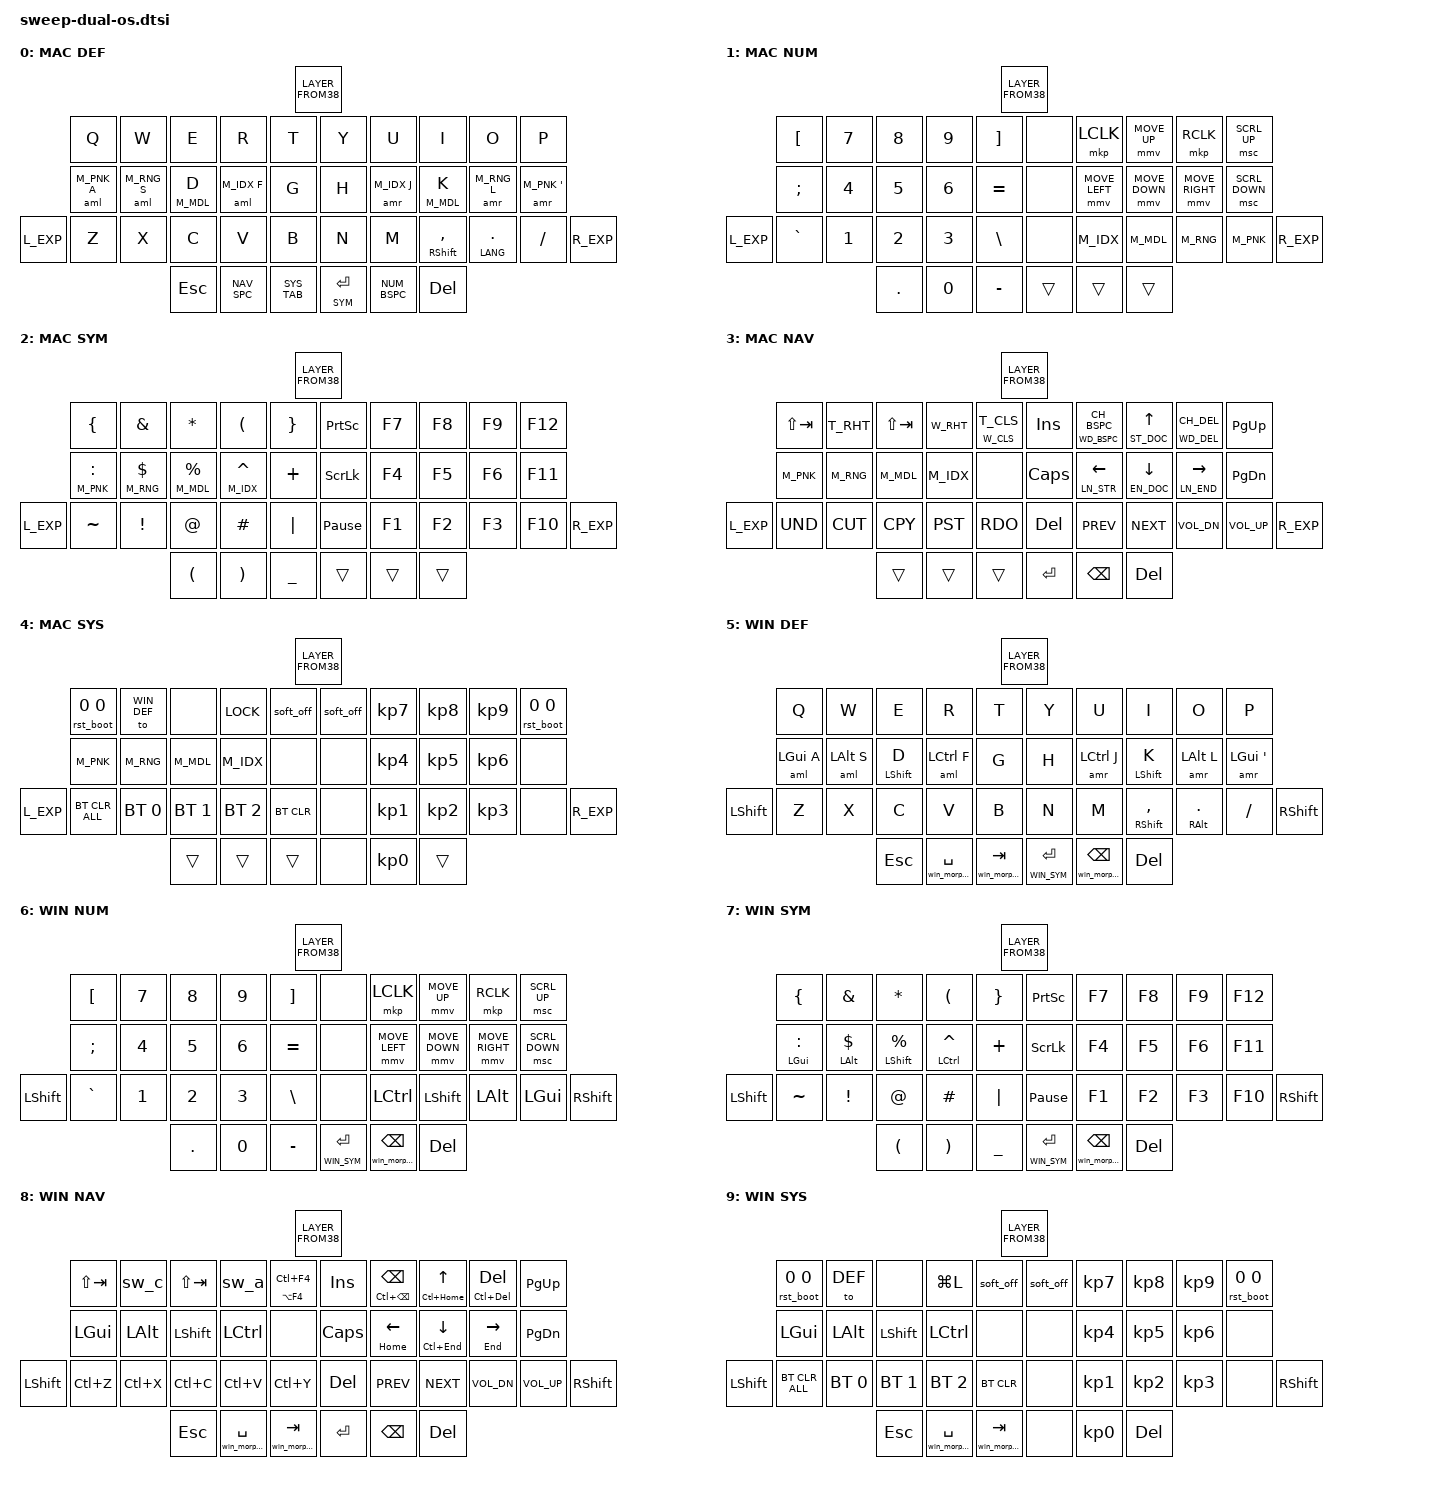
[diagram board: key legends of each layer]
// Generated by scripts/generate_sweep_dual_os.py. Do not edit directly.
// SYS + physical W switches profiles and returns to the new DEF.
#include <behaviors.dtsi>
#include <dt-bindings/zmk/keys.h>
#include <dt-bindings/zmk/bt.h>
#include <dt-bindings/zmk/outputs.h>
#include <behaviors/rgbled_widget.dtsi>

#define DEF 0
#define NUM 1
#define SYM 2
#define NAV 3
#define SYS 4
#define WIN_DEF 5
#define WIN_NUM 6
#define WIN_SYM 7
#define WIN_NAV 8
#define WIN_SYS 9

#include "shortcut.dtsi"
#include "behaviors.dtsi"
#include "mouse.dtsi"
#include "macros.dtsi"
#include "combos.dtsi"

/ {
    behaviors {
        win_morph_num0: win_morph_num0 {
            compatible = "zmk,behavior-mod-morph";
            #binding-cells = <0>;
            bindings = <&mo WIN_NUM>, <&to WIN_NUM>;
            mods = <(MOD_LSFT)>;
        };
        win_num_ht: win_num_layer_hold-tap {
            compatible = "zmk,behavior-hold-tap";
            #binding-cells = <2>;
            tapping-term-ms = <200>;
            quick-tap-ms = <QUICK_TAP_MS>;
            flavor = "balanced";
            bindings = <&win_morph_num0>, <&kp>;
        };

        win_morph_nav0: win_morph_nav0 {
            compatible = "zmk,behavior-mod-morph";
            #binding-cells = <0>;
            bindings = <&mo WIN_NAV>, <&to WIN_NAV>;
            mods = <(MOD_LSFT)>;
        };
        win_nav_ht: win_nav_layer_hold-tap {
            compatible = "zmk,behavior-hold-tap";
            #binding-cells = <2>;
            tapping-term-ms = <200>;
            quick-tap-ms = <QUICK_TAP_MS>;
            flavor = "balanced";
            bindings = <&win_morph_nav0>, <&kp>;
        };

        win_morph_sys0: win_morph_sys0 {
            compatible = "zmk,behavior-mod-morph";
            #binding-cells = <0>;
            bindings = <&mo WIN_SYS>, <&to WIN_SYS>;
            mods = <(MOD_LSFT)>;
        };
        win_sys_ht: win_sys_layer_hold-tap {
            compatible = "zmk,behavior-hold-tap";
            #binding-cells = <2>;
            tapping-term-ms = <200>;
            quick-tap-ms = <QUICK_TAP_MS>;
            flavor = "balanced";
            bindings = <&win_morph_sys0>, <&kp>;
        };


    };
    keymap {
        compatible = "zmk,keymap";
        default_layer {
            display-name = "MAC DEF";
            bindings = <LAYER_FROM38( \
                &kp Q, &kp W, &kp E, &kp R, &kp T, &kp Y, &kp U, &kp I, &kp O, &kp P, \
                &aml M_PNK A, &aml M_RNG S, &asl M_MDL D, &aml M_IDX F, &kp G, &kp H, &amr M_IDX J, &asr M_MDL K, &amr M_RNG L, &amr M_PNK SQT, \
                &kp L_EXP, &kp Z, &kp X, &kp C, &kp V, &kp B, &kp N, &kp M, &mt RSHFT COMMA, &mt LANG DOT, &kp SLASH, &kp R_EXP, \
                &kp ESC, NAV_SPC, SYS_TAB, &lt SYM RET, NUM_BSPC, &kp DEL \
            )>;
        };
        number_layer {
            display-name = "MAC NUM";
            bindings = <LAYER_FROM38( \
                &kp LBKT, &kp N7, &kp N8, &kp N9, &kp RBKT, &none, &mkp LCLK, &mmv MOVE_UP, &mkp RCLK, &msc SCRL_UP, \
                &kp SEMI, &kp N4, &kp N5, &kp N6, &kp EQUAL, &none, &mmv MOVE_LEFT, &mmv MOVE_DOWN, &mmv MOVE_RIGHT, &msc SCRL_DOWN, \
                &kp L_EXP, &kp GRAVE, &kp N1, &kp N2, &kp N3, &kp BSLH, &none, &kp M_IDX, &kp M_MDL, &kp M_RNG, &kp M_PNK, &kp R_EXP, \
                &kp DOT, &kp N0, &kp MINUS, &trans, &trans, &trans \
            )>;
        };
        symbol_layer {
            display-name = "MAC SYM";
            bindings = <LAYER_FROM38( \
                &kp LBRC, &kp AMPS, &kp ASTRK, &kp LPAR, &kp RBRC, &kp PSCRN, &kp F7, &kp F8, &kp F9, &kp F12, \
                &mt M_PNK COLON, &mt M_RNG DLLR, &mt M_MDL PRCNT, &mt M_IDX CARET, &kp PLUS, &kp SLCK, &kp F4, &kp F5, &kp F6, &kp F11, \
                &kp L_EXP, &kp TILDE, &kp EXCL, &kp AT, &kp HASH, &kp PIPE, &kp PAUSE_BREAK, &kp F1, &kp F2, &kp F3, &kp F10, &kp R_EXP, \
                &kp LPAR, &kp RPAR, &kp UNDER, &trans, &trans, &trans \
            )>;
        };
        navigation_layer {
            display-name = "MAC NAV";
            bindings = <LAYER_FROM38( \
                &kp LS(TAB), &T_RHT, &kp LS(TAB), &W_RHT, &ht W_CLS T_CLS, &kp INS, &ht WD_BSPC CH_BSPC, &ht ST_DOC UP, &ht WD_DEL CH_DEL, &kp PG_UP, \
                &kp M_PNK, &kp M_RNG, &kp M_MDL, &kp M_IDX, &none, &kp CAPS, &ht LN_STR LEFT, &ht EN_DOC DOWN, &ht LN_END RIGHT, &kp PG_DN, \
                &kp L_EXP, &kp C_UND, &kp C_CUT, &kp C_CPY, &kp C_PST, &kp C_RDO, &kp DEL, &kp C_PREV, &kp C_NEXT, &kp C_VOL_DN, &kp C_VOL_UP, &kp R_EXP, \
                &trans, &trans, &trans, &kp RET, &kp BSPC, &kp DEL \
            )>;
        };
        system_layer {
            display-name = "MAC SYS";
            bindings = <LAYER_FROM38( \
                &rst_boot 0 0, &to WIN_DEF, &none, &kp LOCK, &soft_off, &soft_off, &kp KP_N7, &kp KP_N8, &kp KP_N9, &rst_boot 0 0, \
                &kp M_PNK, &kp M_RNG, &kp M_MDL, &kp M_IDX, &none, &none, &kp KP_N4, &kp KP_N5, &kp KP_N6, &none, \
                &kp L_EXP, &bt BT_CLR_ALL, &bt BT_SEL 0, &bt BT_SEL 1, &bt BT_SEL 2, &bt BT_CLR, &none, &kp KP_N1, &kp KP_N2, &kp KP_N3, &none, &kp R_EXP, \
                &trans, &trans, &trans, &none, &kp KP_N0, &trans \
            )>;
        };
        default_layer_win {
            display-name = "WIN DEF";
            bindings = <LAYER_FROM38( \
                &kp Q, &kp W, &kp E, &kp R, &kp T, &kp Y, &kp U, &kp I, &kp O, &kp P, \
                &aml LGUI A, &aml LALT S, &asl LSHFT D, &aml LCTRL F, &kp G, &kp H, &amr LCTRL J, &asr LSHFT K, &amr LALT L, &amr LGUI SQT, \
                &kp LSHFT, &kp Z, &kp X, &kp C, &kp V, &kp B, &kp N, &kp M, &mt RSHFT COMMA, &mt RALT DOT, &kp SLASH, &kp RSHFT, \
                &kp ESC, &win_nav_ht 0 SPC, &win_sys_ht 0 TAB, &lt WIN_SYM RET, &win_num_ht 0 BSPC, &kp DEL \
            )>;
        };
        number_layer_win {
            display-name = "WIN NUM";
            bindings = <LAYER_FROM38( \
                &kp LBKT, &kp N7, &kp N8, &kp N9, &kp RBKT, &none, &mkp LCLK, &mmv MOVE_UP, &mkp RCLK, &msc SCRL_UP, \
                &kp SEMI, &kp N4, &kp N5, &kp N6, &kp EQUAL, &none, &mmv MOVE_LEFT, &mmv MOVE_DOWN, &mmv MOVE_RIGHT, &msc SCRL_DOWN, \
                &kp LSHFT, &kp GRAVE, &kp N1, &kp N2, &kp N3, &kp BSLH, &none, &kp LCTRL, &kp LSHFT, &kp LALT, &kp LGUI, &kp RSHFT, \
                &kp DOT, &kp N0, &kp MINUS, &lt WIN_SYM RET, &win_num_ht 0 BSPC, &kp DEL \
            )>;
        };
        symbol_layer_win {
            display-name = "WIN SYM";
            bindings = <LAYER_FROM38( \
                &kp LBRC, &kp AMPS, &kp ASTRK, &kp LPAR, &kp RBRC, &kp PSCRN, &kp F7, &kp F8, &kp F9, &kp F12, \
                &mt LGUI COLON, &mt LALT DLLR, &mt LSHFT PRCNT, &mt LCTRL CARET, &kp PLUS, &kp SLCK, &kp F4, &kp F5, &kp F6, &kp F11, \
                &kp LSHFT, &kp TILDE, &kp EXCL, &kp AT, &kp HASH, &kp PIPE, &kp PAUSE_BREAK, &kp F1, &kp F2, &kp F3, &kp F10, &kp RSHFT, \
                &kp LPAR, &kp RPAR, &kp UNDER, &lt WIN_SYM RET, &win_num_ht 0 BSPC, &kp DEL \
            )>;
        };
        navigation_layer_win {
            display-name = "WIN NAV";
            bindings = <LAYER_FROM38( \
                &kp LS(TAB), &sw_c, &kp LS(TAB), &sw_a, &ht LA(F4) LC(F4), &kp INS, &ht LC(BSPC) BSPC, &ht LC(HOME) UP, &ht LC(DEL) DEL, &kp PG_UP, \
                &kp LGUI, &kp LALT, &kp LSHFT, &kp LCTRL, &none, &kp CAPS, &ht HOME LEFT, &ht LC(END) DOWN, &ht END RIGHT, &kp PG_DN, \
                &kp LSHFT, &kp LC(Z), &kp LC(X), &kp LC(C), &kp LC(V), &kp LC(Y), &kp DEL, &kp C_PREV, &kp C_NEXT, &kp C_VOL_DN, &kp C_VOL_UP, &kp RSHFT, \
                &kp ESC, &win_nav_ht 0 SPC, &win_sys_ht 0 TAB, &kp RET, &kp BSPC, &kp DEL \
            )>;
        };
        system_layer_win {
            display-name = "WIN SYS";
            bindings = <LAYER_FROM38( \
                &rst_boot 0 0, &to DEF, &none, &kp LG(L), &soft_off, &soft_off, &kp KP_N7, &kp KP_N8, &kp KP_N9, &rst_boot 0 0, \
                &kp LGUI, &kp LALT, &kp LSHFT, &kp LCTRL, &none, &none, &kp KP_N4, &kp KP_N5, &kp KP_N6, &none, \
                &kp LSHFT, &bt BT_CLR_ALL, &bt BT_SEL 0, &bt BT_SEL 1, &bt BT_SEL 2, &bt BT_CLR, &none, &kp KP_N1, &kp KP_N2, &kp KP_N3, &none, &kp RSHFT, \
                &kp ESC, &win_nav_ht 0 SPC, &win_sys_ht 0 TAB, &none, &kp KP_N0, &kp DEL \
            )>;
        };
    };
};

/ {
    combos {
COMBO(win_esc,      &kp ESC,         LT4 LT3,        WIN_DEF,                 80, 100)
COMBO(win_lpar,     &kp LPAR,        LM2 LM1,        WIN_DEF,                 40, 100)
COMBO(win_rpar,     &kp RPAR,        RM1 RM2,        WIN_DEF,                 40, 100)
COMBO(win_lbkt,     &kp LBKT,        LM3 LM2,        WIN_DEF,                 80, 100)
COMBO(win_rbkt,     &kp RBKT,        RM2 RM3,        WIN_DEF,                 80, 100)
COMBO(win_sel_all,  &kp LC(A),       LM3 LM2,                WIN_NAV,         80, 100)
COMBO(win_key_re,   &key_repeat,     LM2 LM1,                WIN_NAV,         40, 100)
COMBO(win_semi,     &kp SEMI,        RB1 RB2,        WIN_DEF,                 40, 100)
COMBO(win_colon,    &kp COLON,       RB2 RB3,        WIN_DEF,                 80, 100)
COMBO(win_mute,     &kp C_MUTE,      RB3 RB4,                WIN_NAV,         40, 200)
COMBO(win_plpu,     &kp C_PP,        RB1 RB2,                WIN_NAV,         80, 200)
COMBO(win_capswd,   &caps_word,      LM1 RM1,        WIN_DEF,                 80, 200)
COMBO(win_stdio,    &studio_unlock,  LM0 RM0,                    WIN_SYS,     80, 500)
COMBO(win_def,      &to WIN_DEF,         LM1 RM1,            WIN_NUM WIN_NAV WIN_SYS,     80, 200)
COMBO(win_plus,     &kp PLUS,        LM2 LM1,            WIN_NUM,             40, 100)
COMBO(win_minus,    &kp MINUS,       LT2 LT1,            WIN_NUM,             40, 100)
COMBO(win_star,     &kp STAR,        LT2 LM1,            WIN_NUM,             80, 100)
COMBO(win_slash,    &kp SLASH,       LM2 LT1,            WIN_NUM,             80, 100)
COMBO(win_comma,    &kp COMMA,       LB2 LB1,            WIN_NUM,             40, 100)
COMBO(win_dot,      &kp DOT,         LB3 LB2,            WIN_NUM,             80, 100)
COMBO(win_ret,      &kp RET,         LM3 LM2,            WIN_NUM,             80, 100)
COMBO(win_tab,      &kp TAB,         LT3 LT2,            WIN_NUM,             40, 100)
COMBO(win_plus_n,   &kp KP_PLUS,     RM1 RM2,                    WIN_SYS,     40, 100)
COMBO(win_minus_n,  &kp KP_MINUS,    RT1 RT2,                    WIN_SYS,     40, 100)
COMBO(win_star_n,   &kp KP_MULTIPLY, RT1 RM2,                    WIN_SYS,     80, 100)
COMBO(win_slash_n,  &kp KP_DIVIDE,   RM1 RT2,                    WIN_SYS,     80, 100)
COMBO(win_comma_n,  &kp COMMA,       RB1 RB2,                    WIN_SYS,     40, 100)
COMBO(win_dot_n,    &kp KP_DOT,      RB2 RB3,                    WIN_SYS,     80, 100)
COMBO(win_ret_n,    &kp RET,         RM2 RM3,                    WIN_SYS,     80, 100)
COMBO(win_tab_n,    &kp TAB,         RT2 RT3,                    WIN_SYS,     40, 100)
    };
};
